# STM32F769NIH6 register map
File version: 1.0
Registers are 32-bit, access not given, reset 0x0 unless marked. A register's access mark holds for its fields unless they carry their own. Offsets are from the block's base; [hi:lo] are bit positions; {n}, {i} and the like mark numbered series; 'fields as' and 'values as' point back to an identical list.

## DFSDM1
Base 0x40017400
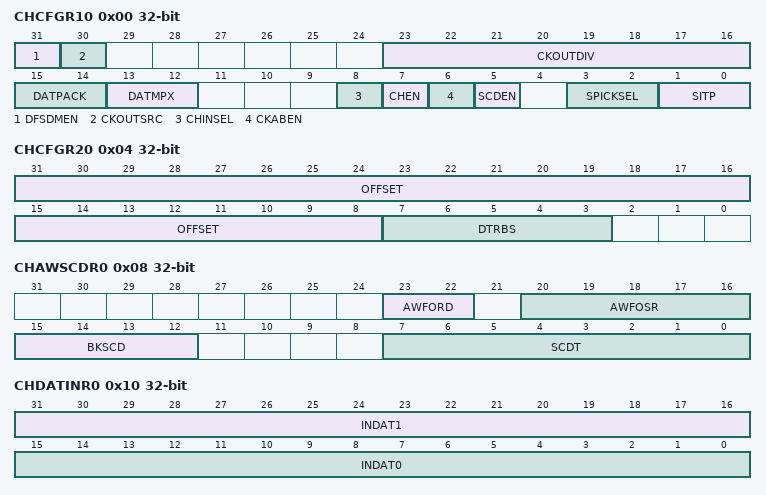
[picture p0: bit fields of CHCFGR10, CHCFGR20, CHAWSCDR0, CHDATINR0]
0x00 CHCFGR10
  [31] DFSDMEN, [30] CKOUTSRC, [23:16] CKOUTDIV, [15:14] DATPACK, [13:12] DATMPX, [8] CHINSEL, [7] CHEN, [6] CKABEN, [5] SCDEN, [3:2] SPICKSEL, [1:0] SITP
0x04 CHCFGR20
  [31:8] OFFSET, [7:3] DTRBS
0x08 CHAWSCDR0
  [23:22] AWFORD, [20:16] AWFOSR, [15:12] BKSCD, [7:0] SCDT
0x0C CHWDATAR0
0x10 CHDATINR0
  [31:16] INDAT1, [15:0] INDAT0
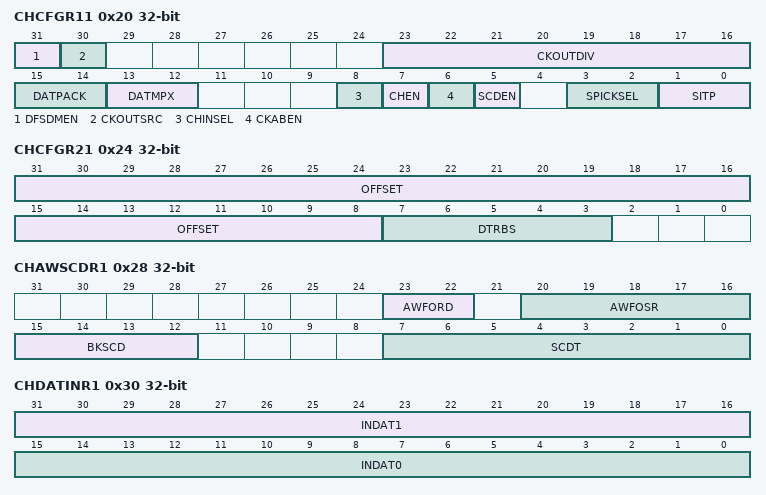
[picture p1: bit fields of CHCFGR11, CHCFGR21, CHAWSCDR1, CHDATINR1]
0x20 CHCFGR11
  fields as CHCFGR10
0x24 CHCFGR21
  [31:8] OFFSET, [7:3] DTRBS
0x28 CHAWSCDR1
  [23:22] AWFORD, [20:16] AWFOSR, [15:12] BKSCD, [7:0] SCDT
0x2C CHWDATAR1
0x30 CHDATINR1
  [31:16] INDAT1, [15:0] INDAT0
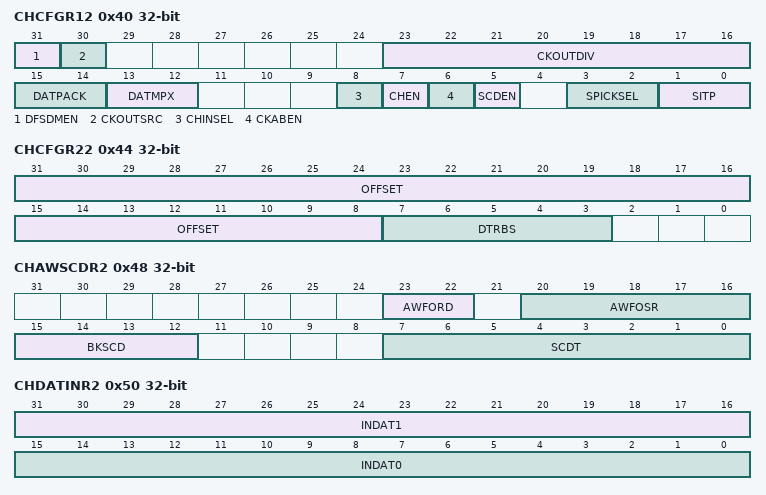
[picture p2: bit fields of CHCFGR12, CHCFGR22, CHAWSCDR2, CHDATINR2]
0x40 CHCFGR12
  fields as CHCFGR10
0x44 CHCFGR22
  [31:8] OFFSET, [7:3] DTRBS
0x48 CHAWSCDR2
  [23:22] AWFORD, [20:16] AWFOSR, [15:12] BKSCD, [7:0] SCDT
0x4C CHWDATAR2
0x50 CHDATINR2
  [31:16] INDAT1, [15:0] INDAT0
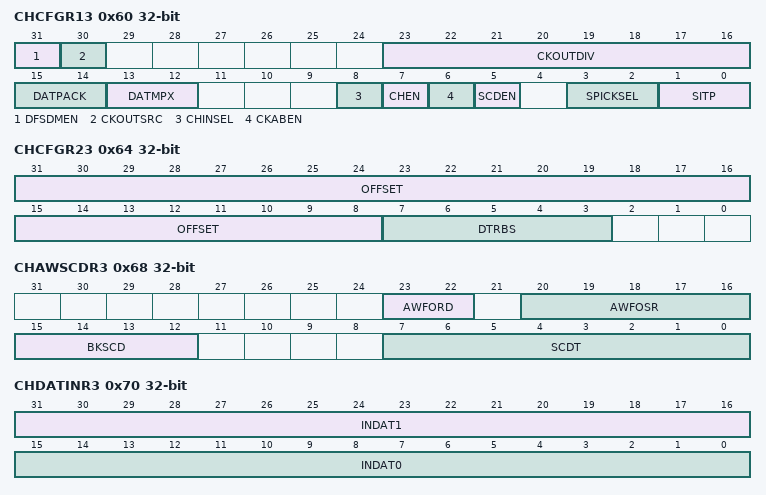
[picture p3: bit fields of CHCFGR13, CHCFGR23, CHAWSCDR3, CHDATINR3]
0x60 CHCFGR13
  fields as CHCFGR10
0x64 CHCFGR23
  [31:8] OFFSET, [7:3] DTRBS
0x68 CHAWSCDR3
  [23:22] AWFORD, [20:16] AWFOSR, [15:12] BKSCD, [7:0] SCDT
0x6C CHWDATAR3
0x70 CHDATINR3
  [31:16] INDAT1, [15:0] INDAT0
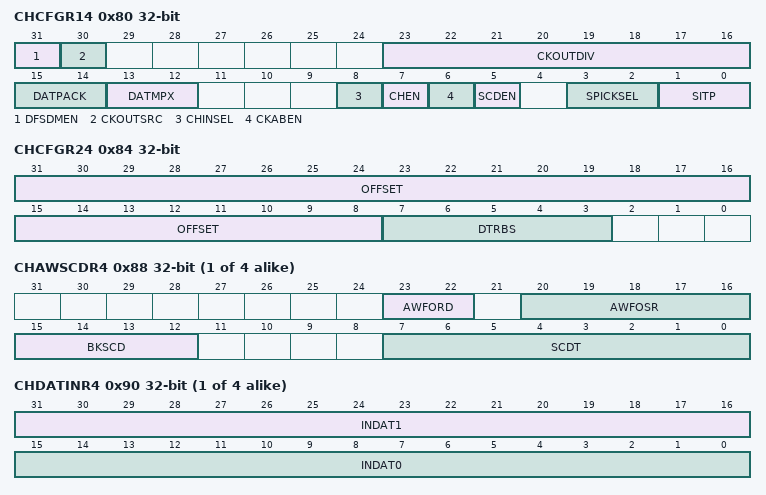
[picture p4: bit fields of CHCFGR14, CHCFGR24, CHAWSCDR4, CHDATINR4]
0x80 CHCFGR14
  fields as CHCFGR10
0x84 CHCFGR24
  [31:8] OFFSET, [7:3] DTRBS
{0x8+0x20*i} CHAWSCDR{i} (i=4..7)
  [23:22] AWFORD, [20:16] AWFOSR, [15:12] BKSCD, [7:0] SCDT
{0xC+0x20*i} CHWDATAR{i} (i=4..7)
{0x10+0x20*i} CHDATINR{i} (i=4..7)
  [31:16] INDAT1, [15:0] INDAT0
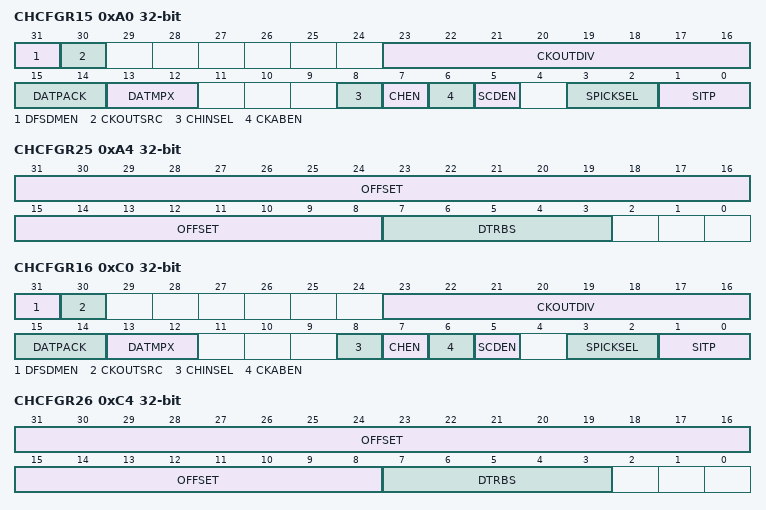
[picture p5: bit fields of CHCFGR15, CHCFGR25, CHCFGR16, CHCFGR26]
0xA0 CHCFGR15
  fields as CHCFGR10
0xA4 CHCFGR25
  [31:8] OFFSET, [7:3] DTRBS
0xC0 CHCFGR16
  fields as CHCFGR10
0xC4 CHCFGR26
  [31:8] OFFSET, [7:3] DTRBS
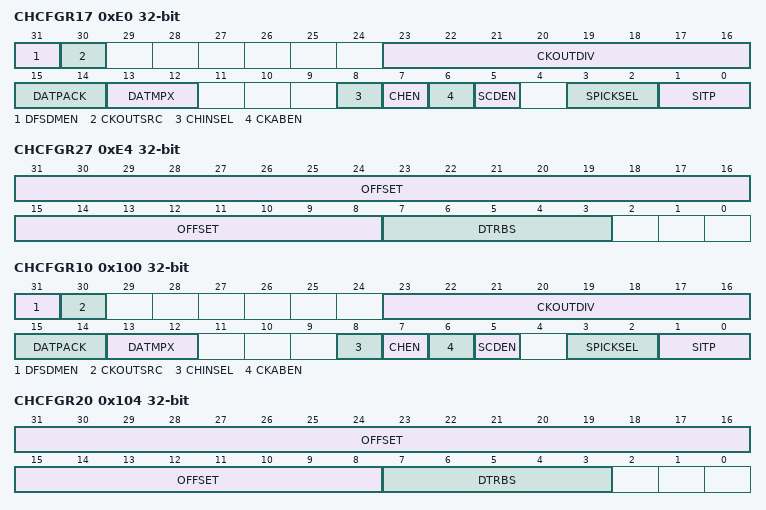
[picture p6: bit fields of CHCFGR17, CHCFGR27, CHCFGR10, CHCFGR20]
0xE0 CHCFGR17
  fields as CHCFGR10
0xE4 CHCFGR27
  [31:8] OFFSET, [7:3] DTRBS
0x100 CHCFGR10
  fields as CHCFGR10
0x104 CHCFGR20
  [31:8] OFFSET, [7:3] DTRBS
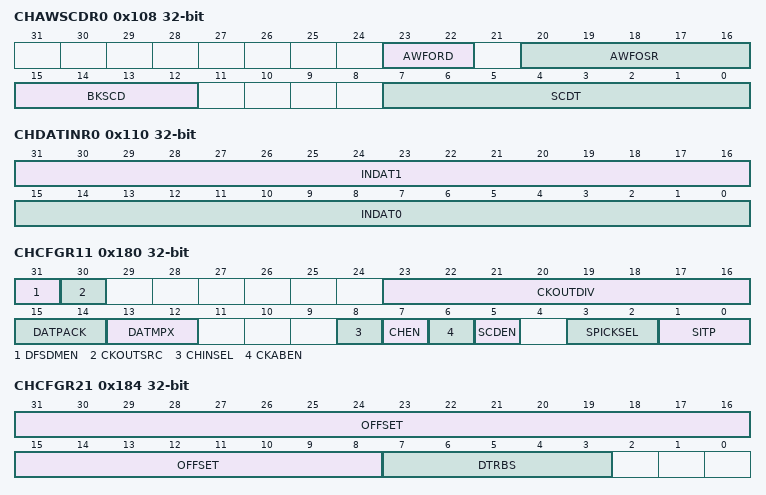
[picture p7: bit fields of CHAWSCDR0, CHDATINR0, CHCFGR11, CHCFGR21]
0x108 CHAWSCDR0
  [23:22] AWFORD, [20:16] AWFOSR, [15:12] BKSCD, [7:0] SCDT
0x10C CHWDATAR0
0x110 CHDATINR0
  [31:16] INDAT1, [15:0] INDAT0
0x180 CHCFGR11
  fields as CHCFGR10
0x184 CHCFGR21
  [31:8] OFFSET, [7:3] DTRBS
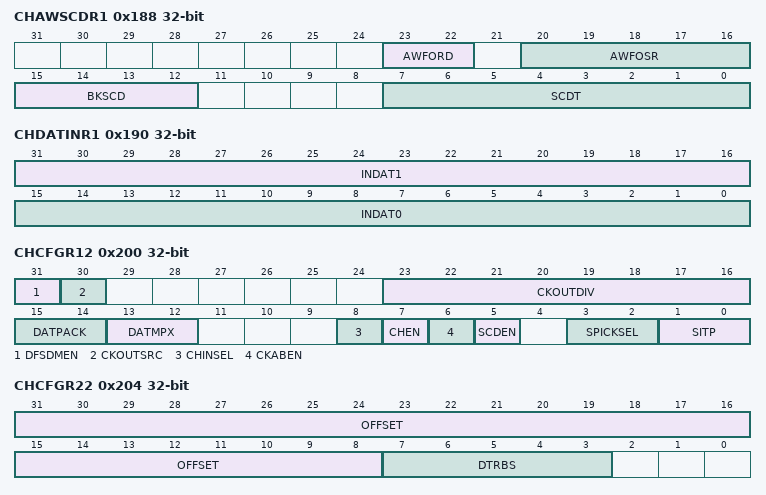
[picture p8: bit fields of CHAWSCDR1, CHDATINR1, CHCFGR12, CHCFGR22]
0x188 CHAWSCDR1
  [23:22] AWFORD, [20:16] AWFOSR, [15:12] BKSCD, [7:0] SCDT
0x18C CHWDATAR1
0x190 CHDATINR1
  [31:16] INDAT1, [15:0] INDAT0
0x200 CHCFGR12
  fields as CHCFGR10
0x204 CHCFGR22
  [31:8] OFFSET, [7:3] DTRBS
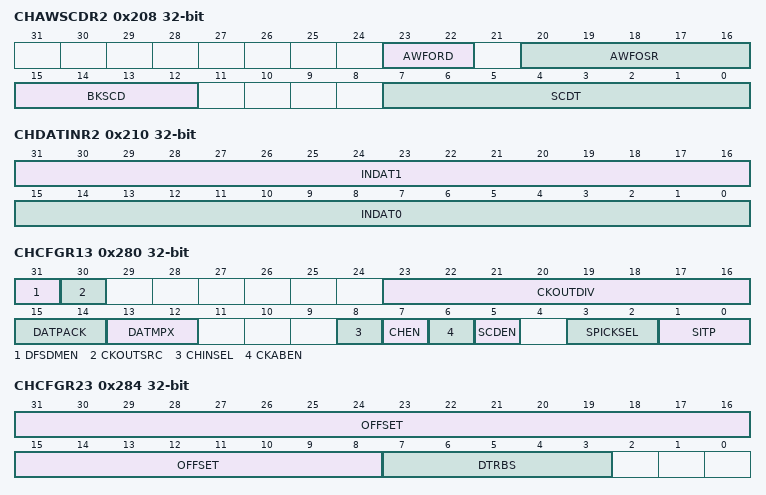
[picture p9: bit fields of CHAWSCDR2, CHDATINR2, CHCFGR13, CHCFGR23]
0x208 CHAWSCDR2
  [23:22] AWFORD, [20:16] AWFOSR, [15:12] BKSCD, [7:0] SCDT
0x20C CHWDATAR2
0x210 CHDATINR2
  [31:16] INDAT1, [15:0] INDAT0
0x280 CHCFGR13
  fields as CHCFGR10
0x284 CHCFGR23
  [31:8] OFFSET, [7:3] DTRBS
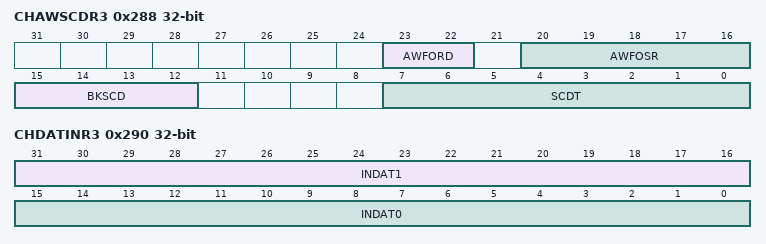
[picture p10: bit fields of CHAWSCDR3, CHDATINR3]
0x288 CHAWSCDR3
  [23:22] AWFORD, [20:16] AWFOSR, [15:12] BKSCD, [7:0] SCDT
0x28C CHWDATAR3
0x290 CHDATINR3
  [31:16] INDAT1, [15:0] INDAT0

## MDIOS
Base 0x40017800
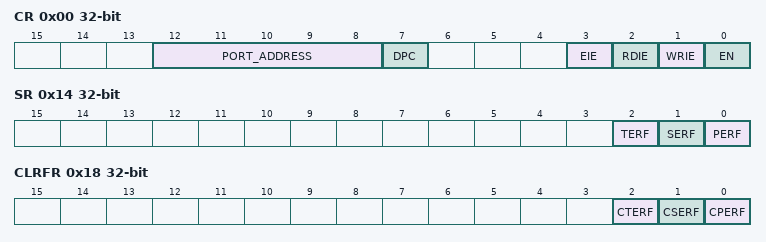
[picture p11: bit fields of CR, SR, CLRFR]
0x00 CR
  [12:8] PORT_ADDRESS, [7] DPC, [3] EIE, [2] RDIE, [1] WRIE, [0] EN
0x04 WRFR
  [31:0] WRF
0x08 CWRFR
  [31:0] CWRF
0x0C RDFR
  [31:0] RDF
0x10 CRDFR
  [31:0] CRDF
0x14 SR
  [2] TERF, [1] SERF, [0] PERF
0x18 CLRFR
  [2] CTERF, [1] CSERF, [0] CPERF
{0x100+4i} DINR{i} (i=0..31)
{0x180+4i} DOUTR{i} (i=0..31)

## GPIOA
Base 0x40020000
Same registers: GPIOB 0x40020400, GPIOC 0x40020800, GPIOD 0x40020C00, GPIOE 0x40021000, GPIOF 0x40021400, GPIOG 0x40021800, GPIOH 0x40021C00, GPIOI 0x40022000, GPIOJ 0x40022400, GPIOK 0x40022800
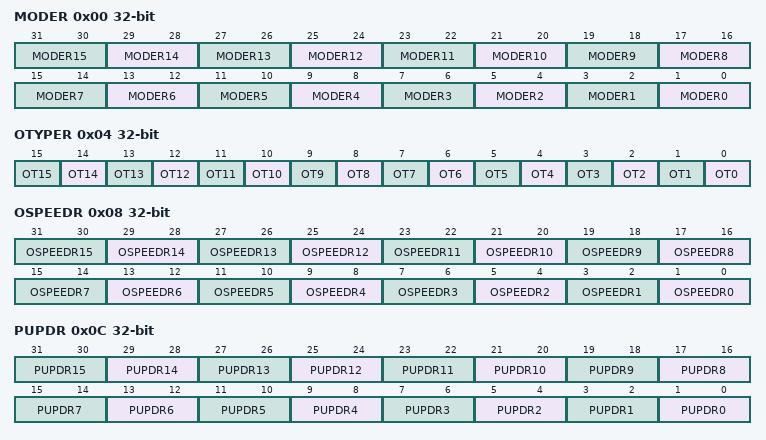
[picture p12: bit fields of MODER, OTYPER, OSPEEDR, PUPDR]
0x00 MODER
  [2n+1:2n] MODER{n} (n=0..15)
0x04 OTYPER
  [n] OT{n} (n=0..15)
0x08 OSPEEDR
  [2n+1:2n] OSPEEDR{n} (n=0..15)
0x0C PUPDR
  [2n+1:2n] PUPDR{n} (n=0..15)
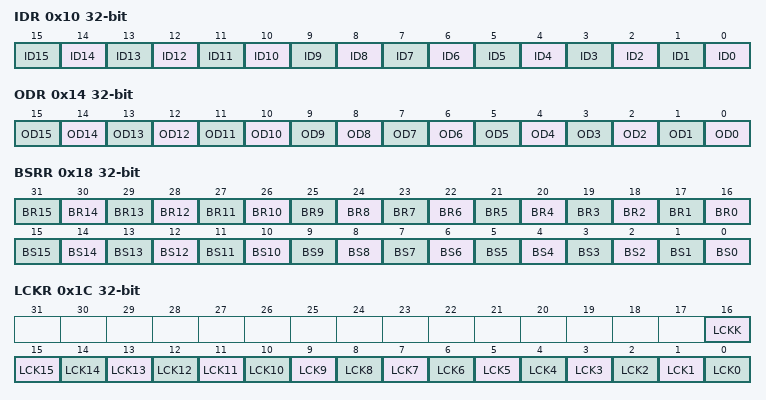
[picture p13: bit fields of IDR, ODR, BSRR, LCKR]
0x10 IDR
  [n] ID{n} (n=0..15)
0x14 ODR
  [n] OD{n} (n=0..15)
0x18 BSRR
  [n+16] BR{n} (n=0..15), [n] BS{n} (n=0..15)
0x1C LCKR
  [16] LCKK, [n] LCK{n} (n=0..15)
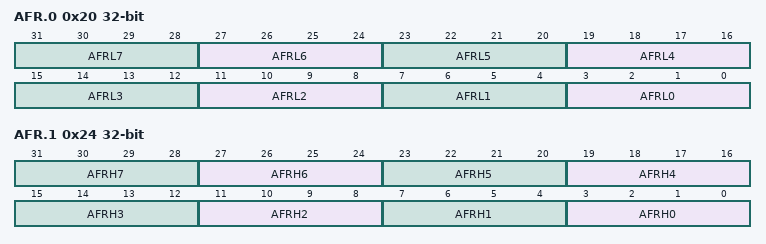
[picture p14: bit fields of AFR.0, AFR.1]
0x20 AFR.0
  [4n+3:4n] AFRL{n} (n=0..7)
0x24 AFR.1
  [4n+3:4n] AFRH{n} (n=0..7)

## CRC
Base 0x40023000
0x00 DR
0x04 IDR 8-bit
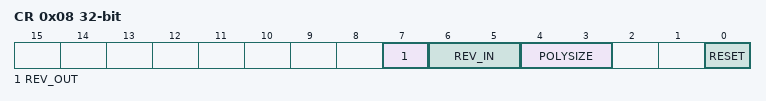
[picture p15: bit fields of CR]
0x08 CR
  [7] REV_OUT, [6:5] REV_IN, [4:3] POLYSIZE, [0] RESET
0x10 INIT
0x14 POL

## FLASH
Base 0x40023C00
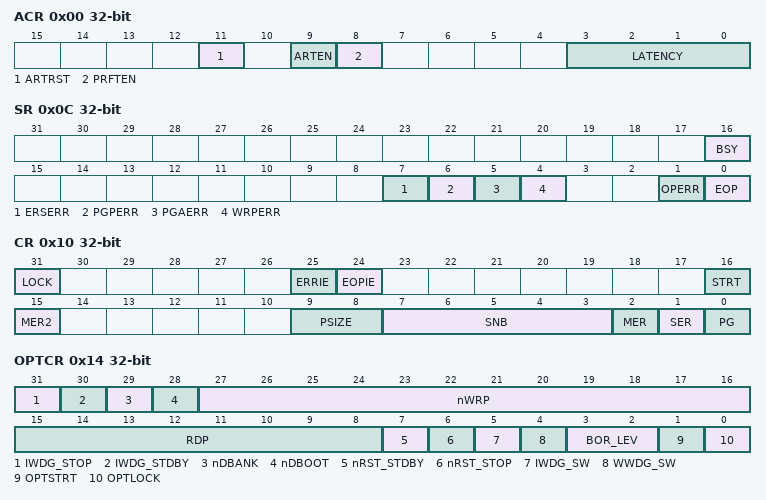
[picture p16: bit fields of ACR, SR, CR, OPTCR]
0x00 ACR
  [11] ARTRST, [9] ARTEN, [8] PRFTEN, [3:0] LATENCY
0x04 KEYR
0x08 OPTKEYR
0x0C SR
  [16] BSY, [7] ERSERR, [6] PGPERR, [5] PGAERR, [4] WRPERR, [1] OPERR, [0] EOP
0x10 CR
  [31] LOCK, [25] ERRIE, [24] EOPIE, [16] STRT, [15] MER2, [9:8] PSIZE, [7:3] SNB, [2] MER, [1] SER, [0] PG
0x14 OPTCR
  [31] IWDG_STOP, [30] IWDG_STDBY, [29] nDBANK, [28] nDBOOT, [27:16] nWRP, [15:8] RDP, [7] nRST_STDBY, [6] nRST_STOP, [5] IWDG_SW, [4] WWDG_SW, [3:2] BOR_LEV, [1] OPTSTRT, [0] OPTLOCK
0x18 OPTCR1
  [31:16] BOOT_ADD1, [15:0] BOOT_ADD0
